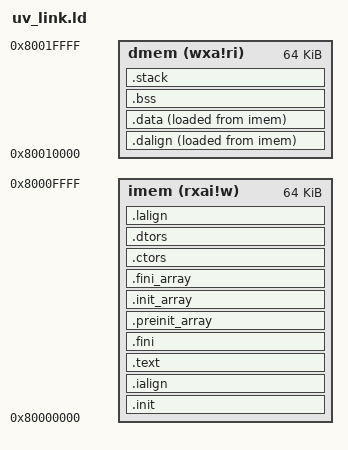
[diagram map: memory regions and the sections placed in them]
/* See LICENSE for license details. */

OUTPUT_ARCH( "riscv" )
ENTRY( _start )

MEMORY
{
  imem (rxai!w) : ORIGIN = 0x80000000, LENGTH = 64K
  dmem (wxa!ri) : ORIGIN = 0x80010000, LENGTH = 64K
}

SECTIONS
{
  __stack_size = DEFINED(__stack_size) ? __stack_size : 8K;

  .init :
  {
    KEEP (*(SORT_NONE(.init)))
  } >imem AT>imem

  .ialign :
  {
    PROVIDE( _inst = . );
  } >imem AT>imem

  .text :
  {
    *(.text.unlikely .text.unlikely.*)
    *(.text.startup .text.startup.*)
    *(.text .text.*)
    *(.gnu.linkonce.t.*)
  } >imem AT>imem 

  .fini :
  {
    KEEP (*(SORT_NONE(.fini)))
  } >imem AT>imem

  . = ALIGN(4);

  PROVIDE( __etext = . );
  PROVIDE( _etext = . );
  PROVIDE( etext = . );

  .preinit_array :
  {
    PROVIDE_HIDDEN (__preinit_array_start = .);
    KEEP (*(.preinit_array))
    PROVIDE_HIDDEN (__preinit_array_end = .);
  } >imem AT>imem

  .init_array :
  {
    PROVIDE_HIDDEN (__init_array_start = .);
    KEEP (*(SORT_BY_INIT_PRIORITY(.init_array.*) SORT_BY_INIT_PRIORITY(.ctors.*)))
    KEEP (*(.init_array EXCLUDE_FILE (*crtbegin.o *crtbegin?.o *crtend.o *crtend?.o ) .ctors))
    PROVIDE_HIDDEN (__init_array_end = .);
  } >imem AT>imem

  .fini_array :
  {
    PROVIDE_HIDDEN (__fini_array_start = .);
    KEEP (*(SORT_BY_INIT_PRIORITY(.fini_array.*) SORT_BY_INIT_PRIORITY(.dtors.*)))
    KEEP (*(.fini_array EXCLUDE_FILE (*crtbegin.o *crtbegin?.o *crtend.o *crtend?.o ) .dtors))
    PROVIDE_HIDDEN (__fini_array_end = .);
  } >imem AT>imem

  .ctors :
  {
    KEEP (*crtbegin.o(.ctors))
    KEEP (*crtbegin?.o(.ctors))
    KEEP (*(EXCLUDE_FILE (*crtend.o *crtend?.o ) .ctors))
    KEEP (*(SORT(.ctors.*)))
    KEEP (*(.ctors))
  } >imem AT>imem

  .dtors :
  {
    KEEP (*crtbegin.o(.dtors))
    KEEP (*crtbegin?.o(.dtors))
    KEEP (*(EXCLUDE_FILE (*crtend.o *crtend?.o ) .dtors))
    KEEP (*(SORT(.dtors.*)))
    KEEP (*(.dtors))
  } >imem AT>imem

  .lalign :
  {
    . = ALIGN(4);
    PROVIDE( _data_lma = . );
  } >imem AT>imem

  .dalign :
  {
    . = ALIGN(4);
    PROVIDE( _data = . );
  } >dmem AT>imem

  .data :
  {
    *(.rdata)
    *(.rodata .rodata.*)
    *(.gnu.linkonce.r.*)
    *(.data .data.*)
    *(.gnu.linkonce.d.*)
    . = ALIGN(8);
    PROVIDE( __global_pointer$ = . + 0x800 );
    *(.sdata .sdata.*)
    *(.gnu.linkonce.s.*)
    . = ALIGN(8);
    *(.srodata.cst16)
    *(.srodata.cst8)
    *(.srodata.cst4)
    *(.srodata.cst2)
    *(.srodata .srodata.*)
  } >dmem AT>imem 

  . = ALIGN(4);
  PROVIDE( _edata = . );
  PROVIDE( edata = . );

  PROVIDE( _fbss = . );
  PROVIDE( __bss_start = . );

  .bss :
  {
    *(.sbss*)
    *(.gnu.linkonce.sb.*)
    *(.bss .bss.*)
    *(.gnu.linkonce.b.*)
    *(COMMON)
    . = ALIGN(4);
  } >dmem AT>dmem

  . = ALIGN(8);
  PROVIDE( __bss_end = . );
  PROVIDE( _end = . );
  PROVIDE( end = . );

  .stack ORIGIN(dmem) + LENGTH(dmem) - __stack_size :
  {
    PROVIDE( _heap_end = . );
    . = __stack_size;
    PROVIDE( _sp = . );
  } >dmem AT>dmem
}
